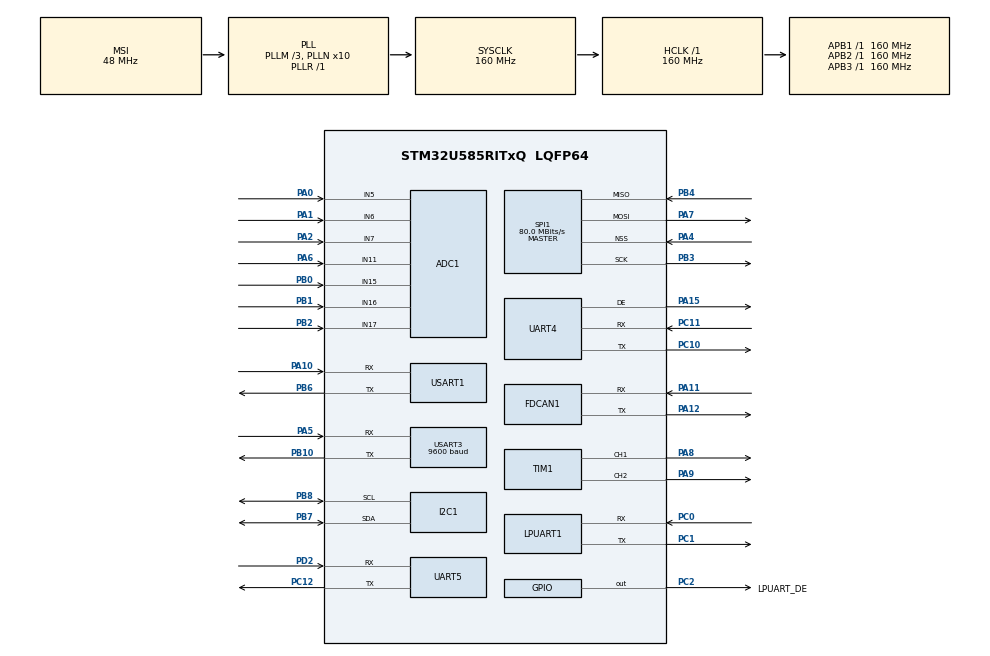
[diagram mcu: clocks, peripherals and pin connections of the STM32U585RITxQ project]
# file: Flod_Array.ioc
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ADC1.NbrOfConversion=1
ADC1.master=1
CORTEX_M33_NS.userName=CORTEX_M33
FDCAN1.CalculateBaudRateNominal=3333333
FDCAN1.CalculateTimeBitNominal=300
FDCAN1.CalculateTimeQuantumNominal=100.0
GPDMA1.CIRCULARMODE_GPDMACH0=ENABLE
GPDMA1.CIRCULARMODE_GPDMACH1=ENABLE
GPDMA1.DIRECTION_GPDMACH0=DMA_PERIPH_TO_MEMORY
GPDMA1.IPHANDLE_GPDMACH0-SIMPLEREQUEST_GPDMACH0=__NULL
GPDMA1.IPHANDLE_GPDMACH1-SIMPLEREQUEST_GPDMACH1=__NULL
GPDMA1.REQUEST_GPDMACH0=GPDMA1_REQUEST_USART3_RX
GPDMA1.REQUEST_GPDMACH1=GPDMA1_REQUEST_UART4_RX
I2C1.Timing=0x30909DEC
LPDMA1.CIRCULARMODE_LPDMACH0=ENABLE
LPDMA1.IPHANDLE_LPDMACH0-SIMPLEREQUEST_LPDMACH0=__NULL
LPDMA1.REQUEST_LPDMACH0=LPDMA1_REQUEST_LPUART1_RX
Mcu.Family=STM32U5
Mcu.Name=STM32U585RITxQ
Mcu.Package=LQFP64
NVIC.GPDMA1_Channel0_IRQn=true\:0\:0\:false\:false\:true\:false\:true\:true
NVIC.GPDMA1_Channel1_IRQn=true\:0\:0\:false\:false\:true\:false\:true\:true
NVIC.I2C1_ER_IRQn=true\:0\:0\:false\:false\:true\:true\:true\:true
NVIC.I2C1_EV_IRQn=true\:0\:0\:false\:false\:true\:true\:true\:true
NVIC.LPDMA1_Channel0_IRQn=true\:0\:0\:false\:false\:true\:false\:true\:true
NVIC.LPUART1_IRQn=true\:0\:0\:false\:false\:true\:true\:true\:true
NVIC.PriorityGroup=NVIC_PRIORITYGROUP_4
NVIC.UART4_IRQn=true\:0\:0\:false\:false\:true\:true\:true\:true
NVIC.USART1_IRQn=true\:0\:0\:false\:false\:true\:true\:true\:true
NVIC.USART3_IRQn=true\:0\:0\:false\:false\:true\:true\:true\:true
PA0.Mode=IN5-Single-Ended
PA0.Signal=ADC1_IN5
PA1.Mode=IN6-Differential
PA1.Signal=ADC1_IN6
PA10.Mode=Asynchronous
PA10.Signal=USART1_RX
PA11.Mode=FDCAN_Activate
PA11.Signal=FDCAN1_RX
PA12.Mode=FDCAN_Activate
PA12.Signal=FDCAN1_TX
PA13\ (JTMS/SWDIO).Mode=Serial_Wire
PA13\ (JTMS/SWDIO).Signal=DEBUG_JTMS-SWDIO
PA14\ (JTCK/SWCLK).Mode=Serial_Wire
PA14\ (JTCK/SWCLK).Signal=DEBUG_JTCK-SWCLK
PA15\ (JTDI).Mode=Hardware Flow Control (RS485)
PA15\ (JTDI).Signal=UART4_DE
PA2.Mode=IN6-Differential
PA2.Signal=ADC1_IN7
PA4.Mode=NSS_Signal_Hard_Input
PA4.Signal=SPI1_NSS
PA5.Mode=Asynchronous
PA5.Signal=USART3_RX
PA6.Mode=IN11-Single-Ended
PA6.Signal=ADC1_IN11
PA7.Mode=Full_Duplex_Master
PA7.Signal=SPI1_MOSI
PA8.Signal=S_TIM1_CH1
PA9.Signal=S_TIM1_CH2
PB0.Mode=IN15-Differential
PB0.Signal=ADC1_IN15
PB1.Mode=IN15-Differential
PB1.Signal=ADC1_IN16
PB10.Mode=Asynchronous
PB10.Signal=USART3_TX
PB2.Mode=IN17-Single-Ended
PB2.Signal=ADC1_IN17
PB3\ (JTDO/TRACESWO).Mode=Full_Duplex_Master
PB3\ (JTDO/TRACESWO).Signal=SPI1_SCK
PB4\ (NJTRST).Mode=Full_Duplex_Master
PB4\ (NJTRST).Signal=SPI1_MISO
PB6.Mode=Asynchronous
PB6.Signal=USART1_TX
PB7.Mode=I2C
PB7.Signal=I2C1_SDA
PB8.Mode=I2C
PB8.Signal=I2C1_SCL
PC0.Mode=Asynchronous
PC0.Signal=LPUART1_RX
PC1.Mode=Asynchronous
PC1.Signal=LPUART1_TX
PC10.Mode=Asynchronous
PC10.Signal=UART4_TX
PC11.Mode=Asynchronous
PC11.Signal=UART4_RX
PC12.Mode=Asynchronous
PC12.Signal=UART5_TX
PC14-OSC32_IN\ (PC14).Mode=LSE-External-Oscillator
PC14-OSC32_IN\ (PC14).Signal=RCC_OSC32_IN
PC15-OSC32_OUT\ (PC15).Mode=LSE-External-Oscillator
PC15-OSC32_OUT\ (PC15).Signal=RCC_OSC32_OUT
PC2.GPIO_Label=LPUART_DE
PC2.Signal=GPIO_Output
PD2.Mode=Asynchronous
PD2.Signal=UART5_RX
PH0-OSC_IN\ (PH0).Mode=HSE-External-Clock-Source
PH0-OSC_IN\ (PH0).Signal=RCC_OSC_IN
ProjectManager.HeapSize=0x200
ProjectManager.StackSize=0x400
ProjectManager.TargetToolchain=STM32CubeIDE
RCC.ADCFreq_Value=16000000
RCC.AHBFreq_Value=160000000
RCC.APB1Freq_Value=160000000
RCC.APB1TimFreq_Value=160000000
RCC.APB2Freq_Value=160000000
RCC.APB2TimFreq_Value=160000000
RCC.APB3Freq_Value=160000000
RCC.CortexFreq_Value=160000000
RCC.EPOD_VALUE=48000000
RCC.HCLKFreq_Value=160000000
RCC.HSE_VALUE=16000000
RCC.HSI48_VALUE=48000000
RCC.HSI_VALUE=16000000
RCC.LSIDIV_VALUE=32000
RCC.MSIClockRange=RCC_MSIRANGE_0
RCC.MSI_VALUE=48000000
RCC.PLL1Q=1
RCC.PLL1R=1
RCC.PLL2FRACN=0
RCC.PLL3FRACN=0
RCC.PLLFRACN=0
RCC.PLLM=3
RCC.PLLN=10
RCC.SYSCLKFreq_VALUE=160000000
RCC.SYSCLKSource=RCC_SYSCLKSOURCE_PLLCLK
RCC.USBFreq_Value=48000000
RCC.VCOOutputFreq_Value=160000000
SH.S_TIM1_CH1.0=TIM1_CH1,PWM Generation1 CH1
SH.S_TIM1_CH2.0=TIM1_CH2,PWM Generation2 CH2
SPI1.CalculateBaudRate=80.0 MBits/s
SPI1.Direction=SPI_DIRECTION_2LINES
SPI1.Mode=SPI_MODE_MASTER
SPI1.VirtualNSS=VM_NSSHARD
SPI1.VirtualType=VM_MASTER
TIM1.Channel-PWM\ Generation1\ CH1=TIM_CHANNEL_1
TIM1.Channel-PWM\ Generation2\ CH2=TIM_CHANNEL_2
USART1.VirtualMode-Asynchronous=VM_ASYNC
USART3.VirtualMode-Asynchronous=VM_ASYNC
USART3.BaudRate=9600
VP_ADC1_TempSens_Input.Mode=IN-TempSens
VP_ADC1_Vbat_Input.Mode=IN-Vbat
VP_ADC1_Vref_Input.Mode=IN-Vrefint
VP_DCACHE1_VS_DCACHE.Mode=DCACHE_Activate
VP_GPDMA1_VS_GPDMACH0.Mode=SIMPLEREQUEST_GPDMACH0
VP_GPDMA1_VS_GPDMACH1.Mode=SIMPLEREQUEST_GPDMACH1
VP_ICACHE_VS_ENABLE_ICACHE_MEMORY.Mode=Memoryregions
VP_ICACHE_VS_ICACHE.Mode=DefaultMode
VP_LPBAMQUEUE_VS_QUEUE.Mode=QUEUEMODE
VP_LPBAM_VS_SIG1.Mode=SmartRun
VP_LPBAM_VS_SIG4.Mode=LPDMA1
VP_LPDMA1_VS_LPDMACH0.Mode=SIMPLEREQUEST_LPDMACH0
VP_MEMORYMAP_VS_MEMORYMAP.Mode=CurAppReg
VP_PWR_VS_SECSignals.Mode=Security/Privilege
VP_PWR_Vdda.Mode=isolationVdda
VP_RTC_VS_RTC_Activate.Mode=RTC_Enabled
VP_RTC_VS_RTC_WakeUp_intern.Mode=WakeUp
board=custom

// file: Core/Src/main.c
/* USER CODE BEGIN Header */
/**
  ******************************************************************************
  * @file           : main.c
  * @brief          : Main program body
  ******************************************************************************
  * @attention
  *
  * Copyright (c) 2026 STMicroelectronics.
  * All rights reserved.
  *
  * This software is licensed under terms that can be found in the LICENSE file
  * in the root directory of this software component.
  * If no LICENSE file comes with this software, it is provided AS-IS.
  *
  ******************************************************************************
  */
/* USER CODE END Header */
#include "main.h"
#include "adc.h"
#include "dcache.h"
#include "fdcan.h"
#include "gpdma.h"
#include "i2c.h"
#include "icache.h"
#include "lpdma.h"
#include "usart.h"
#include "rtc.h"
#include "spi.h"
#include "tim.h"
#include "gpio.h"

/* USER CODE BEGIN Includes */
#include "Communication.h"
#include "Analog.h"
/* USER CODE END Includes */

void SystemClock_Config(void);

int main(void)
{

  /* MCU Configuration--------------------------------------------------------*/

  /* Reset of all peripherals, Initializes the Flash interface and the Systick. */
  HAL_Init();

  /* Configure the system clock */
  SystemClock_Config();

  /* Initialize all configured peripherals */
  MX_GPIO_Init();
  MX_LPDMA1_Init();
  MX_GPDMA1_Init();
  MX_ADC1_Init();
  MX_DCACHE1_Init();
  MX_FDCAN1_Init();
  MX_I2C1_Init();
  MX_LPUART1_UART_Init();
  MX_UART4_Init();
  MX_UART5_Init();
  MX_USART1_UART_Init();
  MX_USART3_UART_Init();
  MX_RTC_Init();
  MX_SPI1_Init();
  MX_ICACHE_Init();
  MX_TIM1_Init();
  /* USER CODE BEGIN 2 */
  Start_UART_Receive();
  Log_Print("Flod_Array boot, log on USART1(PB6,115200)");
  /* USER CODE END 2 */

  /* Infinite loop */
  while (1)
  {

    /* USER CODE BEGIN 3 */

	  //声通/主机通讯
	  process_Host_data();
	  //电机通讯
	  process_Motor_data();
	  //罗盘
	  process_Tcm_data();
  }
  /* USER CODE END 3 */
}

void SystemClock_Config(void)
{
  RCC_OscInitTypeDef RCC_OscInitStruct = {0};
  RCC_ClkInitTypeDef RCC_ClkInitStruct = {0};

  /** Configure the main internal regulator output voltage
  */
  if (HAL_PWREx_ControlVoltageScaling(PWR_REGULATOR_VOLTAGE_SCALE1) != HAL_OK)
  {
    Error_Handler();
  }

  /** Initializes the CPU, AHB and APB buses clocks
  */
  RCC_OscInitStruct.OscillatorType = RCC_OSCILLATORTYPE_HSI|RCC_OSCILLATORTYPE_LSI
                              |RCC_OSCILLATORTYPE_MSI;
  RCC_OscInitStruct.HSIState = RCC_HSI_ON;
  RCC_OscInitStruct.HSICalibrationValue = RCC_HSICALIBRATION_DEFAULT;
  RCC_OscInitStruct.LSIState = RCC_LSI_ON;
  RCC_OscInitStruct.MSIState = RCC_MSI_ON;
  RCC_OscInitStruct.MSICalibrationValue = RCC_MSICALIBRATION_DEFAULT;
  RCC_OscInitStruct.MSIClockRange = RCC_MSIRANGE_0;
  RCC_OscInitStruct.LSIDiv = RCC_LSI_DIV1;
  RCC_OscInitStruct.PLL.PLLState = RCC_PLL_ON;
  RCC_OscInitStruct.PLL.PLLSource = RCC_PLLSOURCE_MSI;
  RCC_OscInitStruct.PLL.PLLMBOOST = RCC_PLLMBOOST_DIV4;
  RCC_OscInitStruct.PLL.PLLM = 3;
  RCC_OscInitStruct.PLL.PLLN = 10;
  RCC_OscInitStruct.PLL.PLLP = 2;
  RCC_OscInitStruct.PLL.PLLQ = 1;
  RCC_OscInitStruct.PLL.PLLR = 1;
  RCC_OscInitStruct.PLL.PLLRGE = RCC_PLLVCIRANGE_1;
  RCC_OscInitStruct.PLL.PLLFRACN = 0;
  if (HAL_RCC_OscConfig(&RCC_OscInitStruct) != HAL_OK)
  {
    Error_Handler();
  }

  /** Initializes the CPU, AHB and APB buses clocks
  */
  RCC_ClkInitStruct.ClockType = RCC_CLOCKTYPE_HCLK|RCC_CLOCKTYPE_SYSCLK
                              |RCC_CLOCKTYPE_PCLK1|RCC_CLOCKTYPE_PCLK2
                              |RCC_CLOCKTYPE_PCLK3;
  RCC_ClkInitStruct.SYSCLKSource = RCC_SYSCLKSOURCE_PLLCLK;
  RCC_ClkInitStruct.AHBCLKDivider = RCC_SYSCLK_DIV1;
  RCC_ClkInitStruct.APB1CLKDivider = RCC_HCLK_DIV1;
  RCC_ClkInitStruct.APB2CLKDivider = RCC_HCLK_DIV1;
  RCC_ClkInitStruct.APB3CLKDivider = RCC_HCLK_DIV1;

  if (HAL_RCC_ClockConfig(&RCC_ClkInitStruct, FLASH_LATENCY_4) != HAL_OK)
  {
    Error_Handler();
  }
}

void Error_Handler(void)
{
  __disable_irq();
  while (1)
  {
  }
}
